# STM32U3C5xx register map
File version: 1.0
Registers are 32-bit, read-write, reset 0x0 unless marked. A register's access mark holds for its fields unless they carry their own. Offsets are from the block's base; [hi:lo] are bit positions; {n}, {i} and the like mark numbered series; 'fields as' and 'values as' point back to an identical list.

## RAMCFG
Base 0x40026000
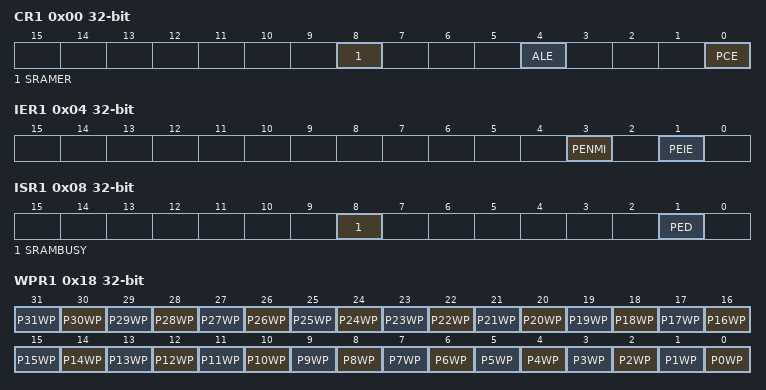
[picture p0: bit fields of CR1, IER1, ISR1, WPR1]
0x00 CR1 — Control Register
  [8] SRAMER — Start Erase
  [4] ALE — Address Latching Enable
  [0] PCE — Parity check Enable
0x04 IER1 — Interrupt enable register
  [3] PENMI — Parity error NMI
  [1] PEIE — Parity error interrupt enable
0x08 ISR1 — Interrupt status register
  [8] SRAMBUSY — SRAM busy with erase operation
  [1] PED — Parity error detected
0x10 PEAR1 — Parity error address register
  [31:0] PEA — Parity error address
0x14 ICR1 — Interrupt clear register
  [1] CPED — Clear parity error detect bit
0x18 WPR1 — Write protection register 1
  [n] P{n}WP (n=0..31) — Write Protection Page {n:02}
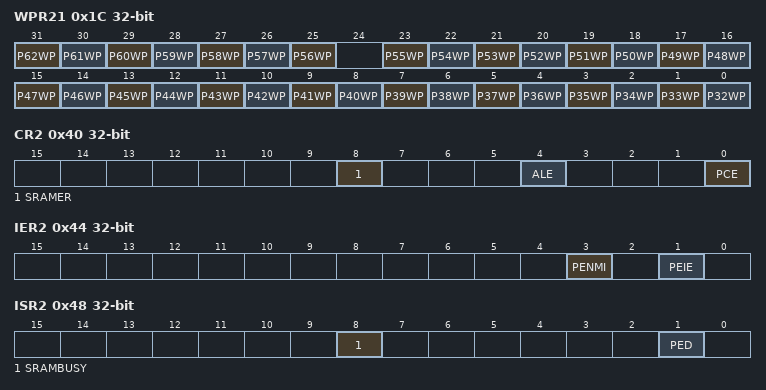
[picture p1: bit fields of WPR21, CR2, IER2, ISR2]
0x1C WPR21 — Write protection register 2
  [n-31] P{n}WP (n=56..62) — Write Protection Page {n}
  [n-32] P{n}WP (n=32..55) — Write Protection Page {n}
0x24 PARKEYR1 — Parity key register
  [7:0] PARKEY — Parity write protection key
0x28 ERKEYR1 — Erase key register
  [7:0] ERASEKEY — Erase write protection key
0x40 CR2 — Control Register
  fields as CR1
0x44 IER2 — Interrupt enable register
  fields as IER1
0x48 ISR2 — Interrupt status register
  fields as ISR1
0x50 PEAR2 — Parity error address register
  [31:0] PEA — Parity error address
0x54 ICR2 — Interrupt clear register
  [1] CPED — Clear parity error detect bit
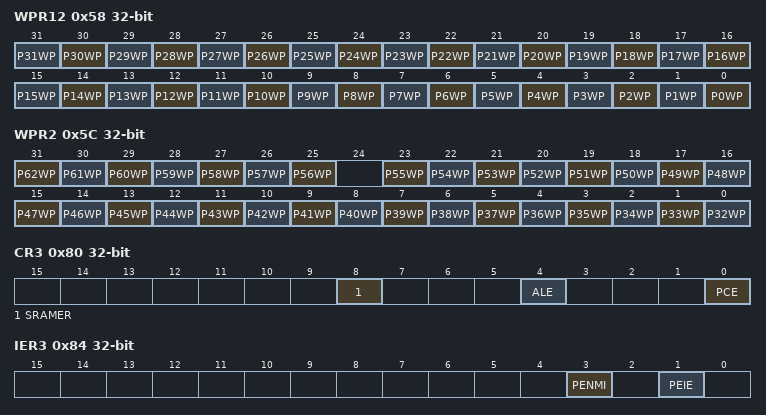
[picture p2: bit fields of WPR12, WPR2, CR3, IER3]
0x58 WPR12 — Write protection register 1
  [n] P{n}WP (n=0..31) — Write Protection Page {n:02}
0x5C WPR2 — Write protection register 2
  fields as WPR21
0x64 PARKEYR2 — Parity key register
  [7:0] PARKEY — Parity write protection key
0x68 ERKEYR2 — Erase key register
  [7:0] ERASEKEY — Erase write protection key
0x80 CR3 — Control Register
  fields as CR1
0x84 IER3 — Interrupt enable register
  fields as IER1
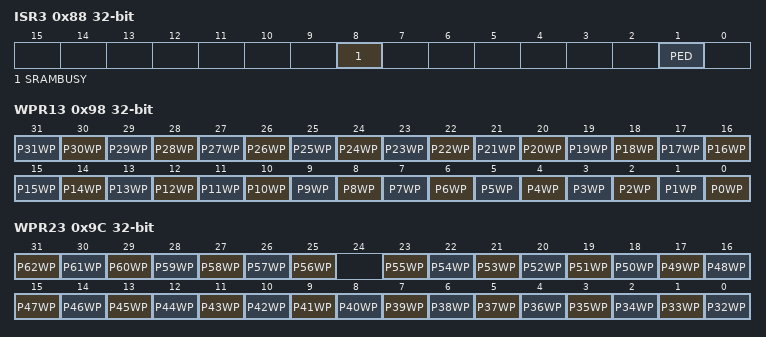
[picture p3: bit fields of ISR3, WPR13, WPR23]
0x88 ISR3 — Interrupt status register
  fields as ISR1
0x90 PEAR3 — Parity error address register
  [31:0] PEA — Parity error address
0x94 ICR3 — Interrupt clear register
  [1] CPED — Clear parity error detect bit
0x98 WPR13 — Write protection register 1
  [n] P{n}WP (n=0..31) — Write Protection Page {n:02}
0x9C WPR23 — Write protection register 2
  fields as WPR21
0xA4 PARKEYR3 — Parity key register
  [7:0] PARKEY — Parity write protection key
0xA8 ERKEYR3 — Erase key register
  [7:0] ERASEKEY — Erase write protection key

## ICACHE — Instruction Cache
Base 0x40030400
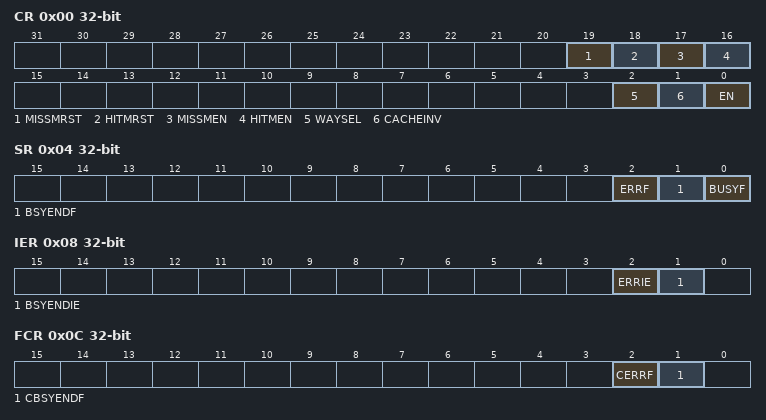
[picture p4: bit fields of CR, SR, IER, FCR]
0x00 CR — ICACHE control register
  [19] MISSMRST — Miss monitor reset
  [18] HITMRST — Hit monitor reset
  [17] MISSMEN — Miss monitor enable
  [16] HITMEN — Hit monitor enable
  [2] WAYSEL — Ways selection
    0=ICACHE_1WAY (1-way cache (direct mapped cache)); 1=ICACHE_2WAYS (2-ways set associative cache (default))
  [1] CACHEINV — Cache invalidation
  [0] EN — Enable
0x04 SR — ICACHE status register
  [2] ERRF — Cache error flag
  [1] BSYENDF — Busy end flag
  [0] BUSYF — Busy flag
0x08 IER — ICACHE interrupt enable register
  [2] ERRIE — Cache error interrupt enable
  [1] BSYENDIE — Busy end interrupt enable
0x0C FCR — ICACHE Flag clear register
  [2] CERRF — Cache error flag clear
  [1] CBSYENDF — Busy end flag clear
0x10 HMONR — ICACHE hit monitor register
  [31:0] HITMON — Cache hit monitor register
0x14 MMONR — ICACHE miss monitor register
  [15:0] MISSMON — Cache miss monitor register
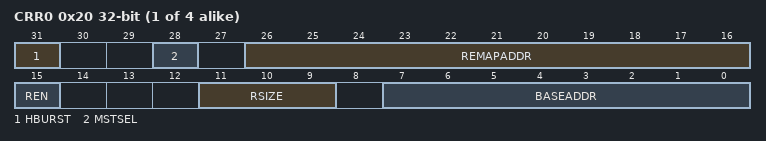
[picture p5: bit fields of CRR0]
{0x20+4i} CRR{i} (i=0..3) — ICACHE region {i} configuration register
  [31] HBURST — Region X output burst type
  [28] MSTSEL — Region X AHB cache master selection
  [26:16] REMAPADDR — Remap address of Region X to be remapped
  [15] REN — Region X enable
  [11:9] RSIZE — Region X size
  [7:0] BASEADDR — Base address of region X to remap

## EXTI — Asynch Interrupt/Event Controller (EXTI)
Base 0x40032000
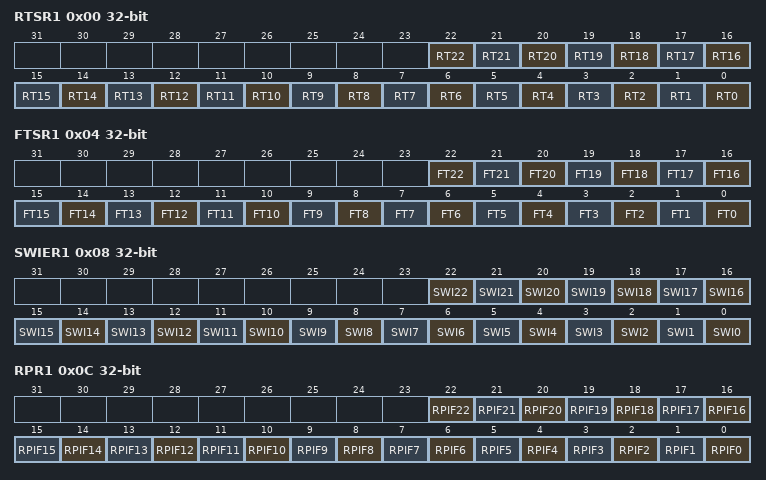
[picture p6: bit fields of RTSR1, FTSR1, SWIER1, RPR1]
0x00 RTSR1 — EXTI Rising Trigger Selection Register 1
  [n] RT{n} (n=0..22) — Rising trigger configuration for input line {n}
0x04 FTSR1 — EXTI Falling Trigger Selection Register 1
  [n] FT{n} (n=0..22) — Falling trigger configuration for input line {n}
0x08 SWIER1 — EXTI Software Interrupt event Register 1
  [n] SWI{n} (n=0..22) — Software Interrupt on line {n}
0x0C RPR1 — EXTI Rising Pending Register 1
  [n] RPIF{n} (n=0..22) — Rising Pending Interrupt Flag on line {n}
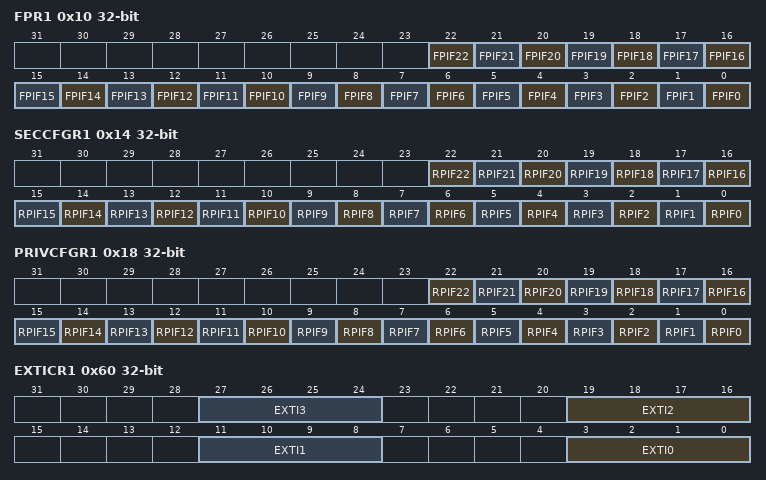
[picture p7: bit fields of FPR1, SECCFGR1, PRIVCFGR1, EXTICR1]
0x10 FPR1 — EXTI Falling Pending Register 1
  [n] FPIF{n} (n=0..22) — Falling Pending Interrupt Flag on line {n}
0x14 SECCFGR1 — EXTI Security Configuration Register 1
  [n] RPIF{n} (n=0..22) — Security enable on line {n}
0x18 PRIVCFGR1 — EXTI Privilege Configuration Register 1
  [n] RPIF{n} (n=0..22) — Privilege enable on line {n}
0x60 EXTICR1 — EXIT External Interrupt Configuration Register, 0x60 -- 0x6C
  [8n+3:8n] EXTI{n} (n=0..3) — EXTI {n} configuration
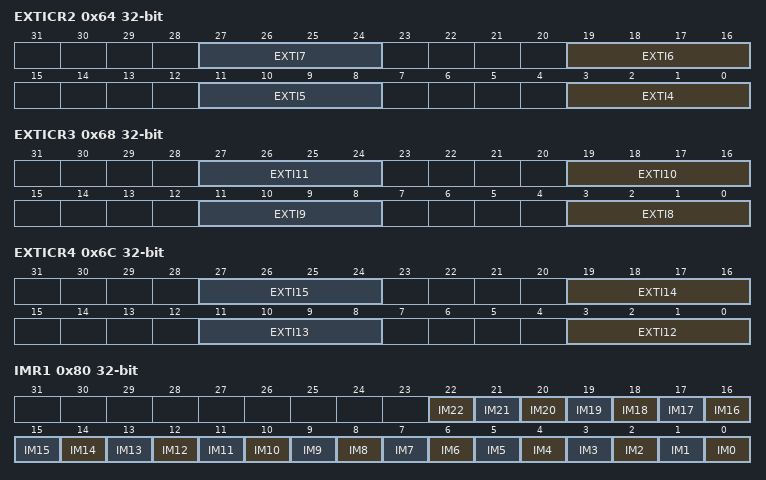
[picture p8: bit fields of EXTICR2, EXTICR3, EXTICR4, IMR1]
0x64 EXTICR2 — EXIT External Interrupt Configuration Register, 0x60 -- 0x6C
  [8n-29:8n-32] EXTI{n} (n=4..7) — EXTI {n} configuration
0x68 EXTICR3 — EXIT External Interrupt Configuration Register, 0x60 -- 0x6C
  [8n-61:8n-64] EXTI{n} (n=8..11) — EXTI {n} configuration
0x6C EXTICR4 — EXIT External Interrupt Configuration Register, 0x60 -- 0x6C
  [8n-93:8n-96] EXTI{n} (n=12..15) — EXTI {n} configuration
0x70 LOCKR — EXTI Lock Register
  [0] LOCK
0x80 IMR1 — EXTI Interrupt Mask Register 1
  [n] IM{n} (n=0..22) — Interrupt Mask on line {n}
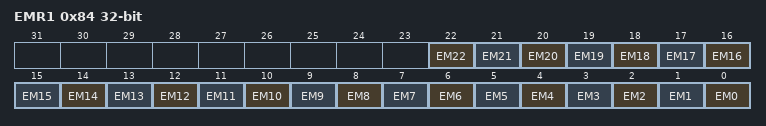
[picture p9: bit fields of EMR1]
0x84 EMR1 — EXTI Event Mask Register 1
  [n] EM{n} (n=0..22) — Event Mask on line {n}
